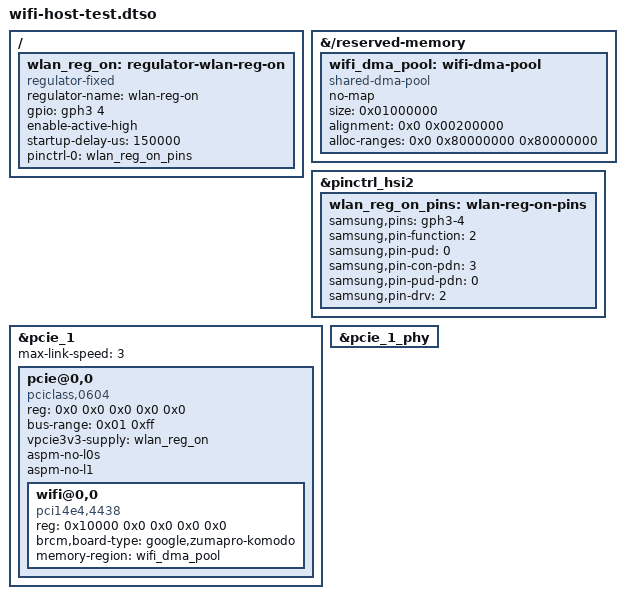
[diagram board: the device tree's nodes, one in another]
// SPDX-License-Identifier: GPL-2.0-only
/* Komodo MP1.0: enable only the BCM4390 PCIe host for enumeration. */
/dts-v1/;
/plugin/;


/ {
	fragment@4 {
		target-path = "/";
		__overlay__ {
			wlan_reg_on: regulator-wlan-reg-on {
				compatible = "regulator-fixed";
				regulator-name = "wlan-reg-on";
				gpio = <&gph3 4 0>;
				enable-active-high;
				startup-delay-us = <150000>;
				pinctrl-names = "default";
				pinctrl-0 = <&wlan_reg_on_pins>;
			};
		};
	};
};

&{/reserved-memory} {
	wifi_dma_pool: wifi-dma-pool {
		compatible = "shared-dma-pool";
		no-map;
		size = <0x01000000>;
		alignment = <0x0 0x00200000>;
		alloc-ranges = <0x0 0x80000000 0x80000000>;
	};
};

&pinctrl_hsi2 {
	status = "okay";
	wlan_reg_on_pins: wlan-reg-on-pins {
		samsung,pins = "gph3-4";
		samsung,pin-function = <2>;
		samsung,pin-pud = <0>;
		samsung,pin-con-pdn = <3>;
		samsung,pin-pud-pdn = <0>;
		samsung,pin-drv = <2>;
	};
};

&pcie_1 {
	status = "okay";
	max-link-speed = <3>;

	pcie@0,0 {
		compatible = "pciclass,0604";
		device_type = "pci";
		reg = <0x0 0x0 0x0 0x0 0x0>;
		bus-range = <0x01 0xff>;
		#address-cells = <3>;
		#size-cells = <2>;
		ranges;
		vpcie3v3-supply = <&wlan_reg_on>;
		aspm-no-l0s;
		aspm-no-l1;

		wifi@0,0 {
			compatible = "pci14e4,4438";
			reg = <0x10000 0x0 0x0 0x0 0x0>;
			brcm,board-type = "google,zumapro-komodo";
			memory-region = <&wifi_dma_pool>;
		};
	};
};

&pcie_1_phy {
	status = "okay";
};
